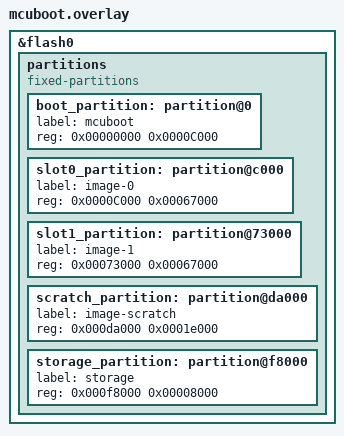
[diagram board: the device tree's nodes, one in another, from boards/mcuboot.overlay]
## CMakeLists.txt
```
# SPDX-License-Identifier: Apache-2.0

cmake_minimum_required(VERSION 3.20.0)

list(APPEND DTC_OVERLAY_FILE "${CMAKE_CURRENT_LIST_DIR}/boards/mcuboot.overlay")

list(APPEND mcuboot_OVERLAY_CONFIG "${CMAKE_CURRENT_LIST_DIR}/boards/mcuboot.conf")
list(APPEND mcuboot_DTC_OVERLAY_FILE "${CMAKE_CURRENT_LIST_DIR}/boards/mcuboot.overlay")

find_package(Zephyr REQUIRED HINTS $ENV{ZEPHYR_BASE})
project(hello_world)

target_sources(app PRIVATE src/main.c)
```

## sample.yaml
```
sample:
  name: Hello World sample
common:
  build_only: true
  integration_platforms:
    - connectkit_nrf52840
    - dongle_nrf52840
tests:
  sample.hello_world: {}
```

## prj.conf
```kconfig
# nothing here
CONFIG_BOOTLOADER_MCUBOOT=y
```

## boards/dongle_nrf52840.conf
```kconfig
#
# Copyright (c) 2016-2023 Makerdiary
#
# SPDX-License-Identifier: Apache-2.0
#

CONFIG_SERIAL=y
CONFIG_CONSOLE=y
CONFIG_UART_CONSOLE=y
CONFIG_UART_LINE_CTRL=y

# USB subsystem configuration
CONFIG_USB_DEVICE_STACK=y
CONFIG_USB_DEVICE_PRODUCT="Zephyr USB Console"
CONFIG_USB_DEVICE_INITIALIZE_AT_BOOT=y
```

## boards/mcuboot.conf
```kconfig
CONFIG_MULTITHREADING=y
```

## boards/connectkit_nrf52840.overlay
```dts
/*
 * Copyright (c) 2016-2023 Makerdiary
 *
 * SPDX-License-Identifier: Apache-2.0
 */

/ {
    chosen {
        zephyr,console = &cdc_acm_uart0;
    };
};

&zephyr_udc0 {
    cdc_acm_uart0: cdc_acm_uart0 {
        compatible = "zephyr,cdc-acm-uart";
    };
};
```

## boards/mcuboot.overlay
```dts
/*
 * Copyright (c) 2016-2023 Makerdiary
 *
 * SPDX-License-Identifier: Apache-2.0
 */

/* Flash partition table compatible with MCUboot bootloader */

/delete-node/ &boot_partition;
/delete-node/ &slot0_partition;
/delete-node/ &storage_partition;

&flash0 {
	partitions {
		compatible = "fixed-partitions";
		#address-cells = <1>;
		#size-cells = <1>;

		boot_partition: partition@0 {
			label = "mcuboot";
			reg = <0x00000000 0x0000C000>;
		};
		slot0_partition: partition@c000 {
			label = "image-0";
			reg = <0x0000C000 0x00067000>;
		};
		slot1_partition: partition@73000 {
			label = "image-1";
			reg = <0x00073000 0x00067000>;
		};
		scratch_partition: partition@da000 {
			label = "image-scratch";
			reg = <0x000da000 0x0001e000>;
		};

		/*
		 * The flash starting at 0x000f8000 and ending at
		 * 0x000fffff is reserved for use by the application.
		 */

		/*
		 * Storage partition will be used by FCB/LittleFS/NVS
		 * if enabled.
		 */
		storage_partition: partition@f8000 {
			label = "storage";
			reg = <0x000f8000 0x00008000>;
		};
	};
};
```

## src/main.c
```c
/*
 * Copyright (c) 2016-2023 Makerdiary
 *
 * SPDX-License-Identifier: Apache-2.0
 */

#include <zephyr/kernel.h>
#include <zephyr/sys/printk.h>

int main(void)
{
    while (1) {
        printk("Hello World with MCUboot enabled! %s\n", CONFIG_BOARD);
        k_sleep(K_SECONDS(1));
    }
    return 0;
}
```
